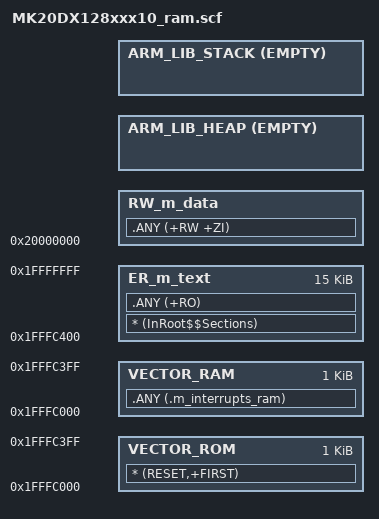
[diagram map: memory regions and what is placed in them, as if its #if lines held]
#! armcc -E
/*
** ###################################################################
**     Processors:          MK20DX128VLQ10
**                          MK20DX128VMD10
**
**     Compiler:            Keil ARM C/C++ Compiler
**     Reference manual:    K20P144M100SF2V2RM Rev. 2, Jun 2012
**     Version:             rev. 1.6, 2014-10-14
**     Build:               b150602
**
**     Abstract:
**         Linker file for the Keil ARM C/C++ Compiler
**
**     Copyright (c) 2015 Freescale Semiconductor, Inc.
**     All rights reserved.
**
**     Redistribution and use in source and binary forms, with or without modification,
**     are permitted provided that the following conditions are met:
**
**     o Redistributions of source code must retain the above copyright notice, this list
**       of conditions and the following disclaimer.
**
**     o Redistributions in binary form must reproduce the above copyright notice, this
**       list of conditions and the following disclaimer in the documentation and/or
**       other materials provided with the distribution.
**
**     o Neither the name of Freescale Semiconductor, Inc. nor the names of its
**       contributors may be used to endorse or promote products derived from this
**       software without specific prior written permission.
**
**     THIS SOFTWARE IS PROVIDED BY THE COPYRIGHT HOLDERS AND CONTRIBUTORS "AS IS" AND
**     ANY EXPRESS OR IMPLIED WARRANTIES, INCLUDING, BUT NOT LIMITED TO, THE IMPLIED
**     WARRANTIES OF MERCHANTABILITY AND FITNESS FOR A PARTICULAR PURPOSE ARE
**     DISCLAIMED. IN NO EVENT SHALL THE COPYRIGHT HOLDER OR CONTRIBUTORS BE LIABLE FOR
**     ANY DIRECT, INDIRECT, INCIDENTAL, SPECIAL, EXEMPLARY, OR CONSEQUENTIAL DAMAGES
**     (INCLUDING, BUT NOT LIMITED TO, PROCUREMENT OF SUBSTITUTE GOODS OR SERVICES;
**     LOSS OF USE, DATA, OR PROFITS; OR BUSINESS INTERRUPTION) HOWEVER CAUSED AND ON
**     ANY THEORY OF LIABILITY, WHETHER IN CONTRACT, STRICT LIABILITY, OR TORT
**     (INCLUDING NEGLIGENCE OR OTHERWISE) ARISING IN ANY WAY OUT OF THE USE OF THIS
**     SOFTWARE, EVEN IF ADVISED OF THE POSSIBILITY OF SUCH DAMAGE.
**
**     http:                 www.freescale.com
**     mail:                 support@freescale.com
**
** ###################################################################
*/

#define m_interrupts_start             0x1FFFC000
#define m_interrupts_size              0x00000400

#define m_text_start                   0x1FFFC400
#define m_text_size                    0x00003C00

#define m_data_start                   0x20000000
#define m_data_size                    0x00004000

/* Sizes */
#if (defined(__stack_size__))
  #define Stack_Size                   __stack_size__
#else
  #define Stack_Size                   0x0400
#endif

#if (defined(__heap_size__))
  #define Heap_Size                    __heap_size__
#else
  #define Heap_Size                    0x0400
#endif

LR_m_text m_text_start m_text_size {   ; load region size_region
  ER_m_text m_text_start m_text_size { ; load address = execution address
    * (InRoot$$Sections)
    .ANY (+RO)
  }
  RW_m_data m_data_start m_data_size-Stack_Size-Heap_Size { ; RW data
    .ANY (+RW +ZI)
  }
  ARM_LIB_HEAP +0 EMPTY Heap_Size {    ; Heap region growing up
  }
  ARM_LIB_STACK m_data_start+m_data_size EMPTY -Stack_Size { ; Stack region growing down
  }
}

LR_m_interrupts m_interrupts_start m_interrupts_size {
  VECTOR_ROM m_interrupts_start m_interrupts_size { ; load address = execution address
    * (RESET,+FIRST)
  }
}

LR_m_interrupts_ram m_interrupts_start m_interrupts_size {
  VECTOR_RAM m_interrupts_start m_interrupts_size { ; load address = execution address
    .ANY (.m_interrupts_ram)
  }
}

